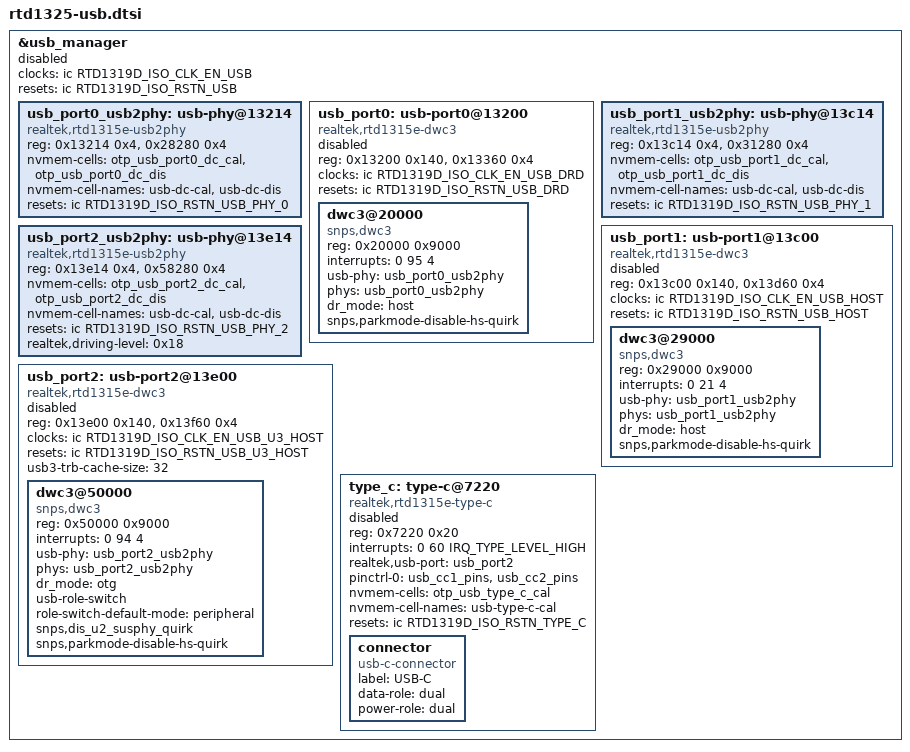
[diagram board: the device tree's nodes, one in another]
// SPDX-License-Identifier: (GPL-2.0-or-later OR BSD-2-Clause)
/*
 * Realtek RTD1315e SoC USB
 *
 * Copyright (c) 2022 Realtek Semiconductor Corp.
 */

&usb_manager {
	clocks = <&ic RTD1319D_ISO_CLK_EN_USB>; /* clk_en_usb */
	clock-names = "usb"; /*clk_en_usb*/

	resets = <&ic RTD1319D_ISO_RSTN_USB>; /* rstn_usb */
	reset-names = "usb"; /* rstn_usb */

	status = "disabled";

	usb_port0_usb2phy: usb-phy@13214 {
		compatible = "realtek,rtd1315e-usb2phy";
		reg = <0x13214 0x4>, <0x28280 0x4>;
		#phy-cells = <0>;
		nvmem-cells = <&otp_usb_port0_dc_cal>, <&otp_usb_port0_dc_dis>;
		nvmem-cell-names = "usb-dc-cal", "usb-dc-dis";

		resets = <&ic RTD1319D_ISO_RSTN_USB_PHY_0>; /* rstn_usb_phy0 (port0 u2phy) */
		reset-names = "u2phy"; /* rstn_usb_phy0 (port0 u2phy) */
	};

	usb_port0: usb-port0@13200 {
		compatible = "realtek,rtd1315e-dwc3", "realtek,rtd-dwc3";
		reg = <0x13200 0x140>, <0x13360 0x4>;
		#address-cells = <1>;
		#size-cells = <1>;
		ranges;
		status = "disabled";

		clocks = <&ic RTD1319D_ISO_CLK_EN_USB_DRD>;  /* clk_en_usb_drd (port0 phy to u2drd clock) */
		clock-names = "usb-mac"; /* clk_en_usb_drd (port0 phy to u2drd clock) */
		resets = <&ic RTD1319D_ISO_RSTN_USB_DRD>; /* rstn_usb_u2drd (port0) */
		reset-names = "usb-mac"; /* rstn_usb_u2drd (port0) */

		dwc3@20000 {
			compatible = "snps,dwc3";
			reg = <0x20000 0x9000>;
			interrupts = <0 95 4>;
			usb-phy = <&usb_port0_usb2phy>;
			phys = <&usb_port0_usb2phy>;
			phy-names = "usb2-phy";
			dr_mode = "host";
			snps,parkmode-disable-hs-quirk; // disable usb2.0 park mode
		};
	};

	usb_port1_usb2phy: usb-phy@13c14 {
		compatible = "realtek,rtd1315e-usb2phy";
		reg = <0x13c14 0x4>, <0x31280 0x4>;
		#phy-cells = <0>;
		nvmem-cells = <&otp_usb_port1_dc_cal>, <&otp_usb_port1_dc_dis>;
		nvmem-cell-names = "usb-dc-cal", "usb-dc-dis";

		resets = <&ic RTD1319D_ISO_RSTN_USB_PHY_1>; /* rstn_usb_phy1 (port1 u2phy) */
		reset-names = "u2phy"; /* rstn_usb_phy1 (port1 u2phy) */
	};

	usb_port1: usb-port1@13c00 {
		compatible = "realtek,rtd1315e-dwc3", "realtek,rtd-dwc3";
		reg = <0x13c00 0x140>, <0x13d60 0x4>;
		#address-cells = <1>;
		#size-cells = <1>;
		ranges;
		status = "disabled";

		clocks = <&ic RTD1319D_ISO_CLK_EN_USB_HOST>;  /* clk_en_usb_host0 (port1 phy to u2host clock) */
		clock-names = "usb-mac"; /* clk_en_usb_u2host (port1 phy to u2host clock) */
		resets = <&ic RTD1319D_ISO_RSTN_USB_HOST>; /* rstn_usb_u2host(port1) */
		reset-names = "usb-mac"; /* rstn_usb_u2host (port1) */

		dwc3@29000 {
			compatible = "snps,dwc3";
			reg = <0x29000 0x9000>;
			interrupts = <0 21 4>;
			usb-phy = <&usb_port1_usb2phy>;
			phys = <&usb_port1_usb2phy>;
			phy-names = "usb2-phy";
			dr_mode = "host";
			snps,parkmode-disable-hs-quirk; // disable usb2.0 park mode
		};
	};

	usb_port2_usb2phy: usb-phy@13e14 {
		compatible = "realtek,rtd1315e-usb2phy";
		reg = <0x13e14 0x4>, <0x58280 0x4>;
		#phy-cells = <0>;
		nvmem-cells = <&otp_usb_port2_dc_cal>, <&otp_usb_port2_dc_dis>;
		nvmem-cell-names = "usb-dc-cal", "usb-dc-dis";

		resets = <&ic RTD1319D_ISO_RSTN_USB_PHY_2>; /* rstn_usb_phy2 (port2 u2phy) */
		reset-names = "u2phy"; /* rstn_usb_phy2 (port2 u2phy) */

		realtek,driving-level = <0x18>;
	};

	usb_port2: usb-port2@13e00 {
		compatible = "realtek,rtd1315e-dwc3", "realtek,rtd-dwc3";
		reg = <0x13e00 0x140>, <0x13f60 0x4>;
		#address-cells = <1>;
		#size-cells = <1>;
		ranges;

		clocks = <&ic RTD1319D_ISO_CLK_EN_USB_U3_HOST>;  /* clk_en_usb_host1 (port2 phy to u3drd clock) */
		clock-names = "usb-mac"; /* clk_en_usb_u3host (port2 phy to u3drd clock) */
		resets = <&ic RTD1319D_ISO_RSTN_USB_U3_HOST>; /* rstn_usb_u3drd (port2) */
		reset-names = "usb-mac"; /* rstn_usb_u3drd (port2) */

		usb3-trb-cache-size = <32>; /* for xhci controller */
		status = "disabled";

		dwc3@50000 {
			compatible = "snps,dwc3";
			reg = <0x50000 0x9000>;
			interrupts = <0 94 4>;
			usb-phy = <&usb_port2_usb2phy>;
			phys = <&usb_port2_usb2phy>;
			phy-names = "usb2-phy";
			dr_mode = "otg"; /* otg, host, peripheral*/
			usb-role-switch;
			role-switch-default-mode = "peripheral"; /* host, peripheral*/
			snps,dis_u2_susphy_quirk; // Disable u2phy suspend for drd
			snps,parkmode-disable-hs-quirk; // disable usb2.0 park mode
		};
	};

	type_c: type-c@7220 {
		compatible = "realtek,rtd1315e-type-c";
		reg = <0x7220 0x20>;
		#address-cells = <1>;
		#size-cells = <1>;
		ranges;

		interrupts = <0 60 IRQ_TYPE_LEVEL_HIGH>;

		realtek,usb-port = <&usb_port2>;

		pinctrl-names = "default";
		pinctrl-0 = <&usb_cc1_pins>, <&usb_cc2_pins>;

		nvmem-cells = <&otp_usb_type_c_cal>;
		nvmem-cell-names = "usb-type-c-cal";

		resets = <&ic RTD1319D_ISO_RSTN_TYPE_C>; /* rstn_type_c */
		reset-names = "type-c"; /* rstn_type_c */

		/* For connector switch */
		//realtek,connector-switch-gpio = <&gpio 49 GPIO_ACTIVE_HIGH>;
		/* For plug side switch */
		//realtek,plug-side-switch-gpio = <&gpio 53 GPIO_ACTIVE_HIGH>;

		status = "disabled";

		connector {
			compatible = "usb-c-connector";
			label = "USB-C";
			data-role = "dual";
			power-role = "dual";
		};
	};
};
